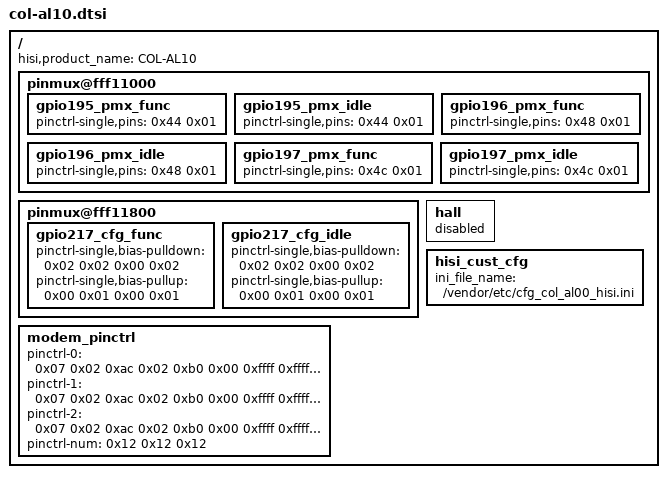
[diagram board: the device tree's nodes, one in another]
/include/ "../col-common.dtsi"

/ {
	hisi,product_name = "COL-AL10";

	pinmux@fff11000 {
		gpio195_pmx_func {
			pinctrl-single,pins = <0x44 0x01>;
		};

		gpio195_pmx_idle {
			pinctrl-single,pins = <0x44 0x01>;
		};

		gpio196_pmx_func {
			pinctrl-single,pins = <0x48 0x01>;
		};

		gpio196_pmx_idle {
			pinctrl-single,pins = <0x48 0x01>;
		};

		gpio197_pmx_func {
			pinctrl-single,pins = <0x4c 0x01>;
		};

		gpio197_pmx_idle {
			pinctrl-single,pins = <0x4c 0x01>;
		};
	};

	pinmux@fff11800 {
		gpio217_cfg_func {
			pinctrl-single,bias-pulldown = <0x02 0x02 0x00 0x02>;
			pinctrl-single,bias-pullup = <0x00 0x01 0x00 0x01>;
		};

		gpio217_cfg_idle {
			pinctrl-single,bias-pulldown = <0x02 0x02 0x00 0x02>;
			pinctrl-single,bias-pullup = <0x00 0x01 0x00 0x01>;
		};
	};

	hall {
		status = "disabled";
	};

	modem_pinctrl {
		pinctrl-0 = <0x07 0x02 0xac 0x02 0xb0 0x00 0xffff 0xffff 0x07 0x05 0xb8 0x00 0xbc 0x00 0x01 0x00 0x07 0x06 0xbc 0x04 0xc0 0x00 0xffff 0xffff 0x07 0x07 0xc0 0x00 0xc4 0x00 0x01 0x00 0x08 0x00 0xc4 0x01 0xc8 0x00 0x01 0x00 0x08 0x01 0xc8 0x01 0xcc 0x00 0x01 0x00 0x08 0x02 0xcc 0x01 0xd0 0x00 0x01 0x00 0x08 0x06 0xdc 0x01 0xe0 0x00 0x01 0x00 0x08 0x07 0xe0 0x01 0xe4 0x00 0x01 0x00 0x0b 0x00 0x124 0x01 0x128 0x00 0xffff 0xffff 0x0b 0x01 0x128 0x01 0x12c 0x02 0xffff 0xffff 0x0b 0x02 0x12c 0x01 0x130 0x00 0xffff 0xffff 0x0b 0x03 0x130 0x01 0x134 0x02 0xffff 0xffff 0x0b 0x06 0x13c 0x01 0x140 0x00 0xffff 0xffff 0x0b 0x07 0x140 0x01 0x144 0x02 0xffff 0xffff 0x0c 0x00 0x144 0x01 0x148 0x00 0xffff 0xffff 0x12 0x05 0xac 0x03 0xdc 0x00 0xffff 0xffff 0x16 0x06 0x10 0x00 0x3c 0x01 0x00 0xffff>;
		pinctrl-1 = <0x07 0x02 0xac 0x02 0xb0 0x00 0xffff 0xffff 0x07 0x05 0xb8 0x00 0xbc 0x00 0xffff 0xffff 0x07 0x06 0xbc 0x04 0xc0 0x00 0xffff 0xffff 0x07 0x07 0xc0 0x00 0xc4 0x00 0xffff 0xffff 0x08 0x00 0xc4 0xffff 0xc8 0xffff 0xffff 0xffff 0x08 0x01 0xc8 0x01 0xcc 0x00 0x01 0x00 0x08 0x02 0xcc 0x01 0xd0 0x00 0x01 0x00 0x08 0x06 0xdc 0x01 0xe0 0x00 0x01 0x00 0x08 0x07 0xe0 0x01 0xe4 0x00 0x01 0x00 0x0b 0x00 0x124 0x01 0x128 0x00 0xffff 0xffff 0x0b 0x01 0x128 0x01 0x12c 0x02 0xffff 0xffff 0x0b 0x02 0x12c 0x01 0x130 0x00 0xffff 0xffff 0x0b 0x03 0x130 0x01 0x134 0x02 0xffff 0xffff 0x0b 0x06 0x13c 0x01 0x140 0x00 0xffff 0xffff 0x0b 0x07 0x140 0x01 0x144 0x02 0xffff 0xffff 0x0c 0x00 0x144 0x01 0x148 0x00 0xffff 0xffff 0x12 0x05 0xac 0x03 0xdc 0x00 0xffff 0xffff 0x16 0x06 0x10 0x00 0x3c 0x01 0x00 0xffff>;
		pinctrl-2 = <0x07 0x02 0xac 0x02 0xb0 0x00 0xffff 0xffff 0x07 0x05 0xb8 0x00 0xbc 0x00 0xffff 0xffff 0x07 0x06 0xbc 0x04 0xc0 0x00 0xffff 0xffff 0x07 0x07 0xc0 0x00 0xc4 0x00 0xffff 0xffff 0x08 0x00 0xc4 0xffff 0xc8 0xffff 0xffff 0xffff 0x08 0x01 0xc8 0x01 0xcc 0x00 0x01 0x00 0x08 0x02 0xcc 0x01 0xd0 0x00 0x01 0x00 0x08 0x06 0xdc 0x01 0xe0 0x00 0x01 0x00 0x08 0x07 0xe0 0x01 0xe4 0x00 0x01 0x00 0x0b 0x00 0x124 0x01 0x128 0x00 0xffff 0xffff 0x0b 0x01 0x128 0x01 0x12c 0x02 0xffff 0xffff 0x0b 0x02 0x12c 0x01 0x130 0x00 0xffff 0xffff 0x0b 0x03 0x130 0x01 0x134 0x02 0xffff 0xffff 0x0b 0x06 0x13c 0x01 0x140 0x00 0xffff 0xffff 0x0b 0x07 0x140 0x01 0x144 0x02 0xffff 0xffff 0x0c 0x00 0x144 0x01 0x148 0x00 0xffff 0xffff 0x12 0x05 0xac 0x03 0xdc 0x00 0xffff 0xffff 0x16 0x06 0x10 0x00 0x3c 0x01 0x00 0xffff>;
		pinctrl-num = <0x12 0x12 0x12>;
	};

	hisi_cust_cfg {
		ini_file_name = "/vendor/etc/cfg_col_al00_hisi.ini";
	};
};
